# DA14682 register map
Vendor: Dialog; Series: DA14682; File version: 1.2
CPU: CM0 r1p0, little endian, MPU, FPU, 3 interrupt priority bits
Registers are 16-bit, read-write, reset 0x0 unless marked. A register's access mark holds for its fields unless they carry their own. Offsets are from the block's base; [hi:lo] are bit positions; {n}, {i} and the like mark numbered series.

## DCDC — DCDC registers
Base 0x50000080
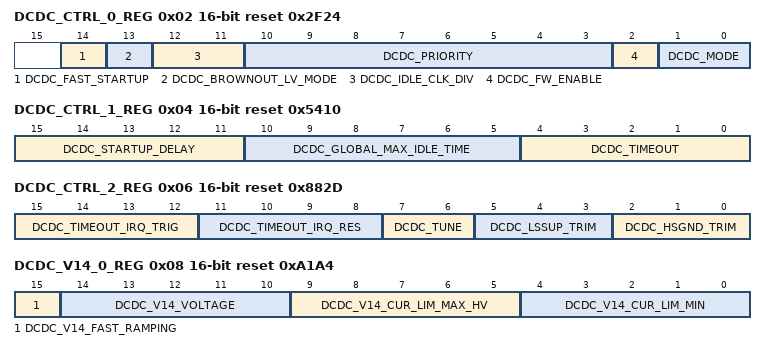
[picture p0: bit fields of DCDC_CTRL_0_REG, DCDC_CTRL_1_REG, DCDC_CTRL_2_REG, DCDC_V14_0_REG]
0x02 DCDC_CTRL_0_REG reset 0x2F24 — DCDC First Control Register
  [14] DCDC_FAST_STARTUP — Set current limit to maximum during initial startup
  [13] DCDC_BROWNOUT_LV_MODE — Switches to low voltage settings when battery voltage drops below 2.5 V
  [12:11] DCDC_IDLE_CLK_DIV — Idle Clock Divider 00 = 2 01 = 4 10 = 8 11 = 16
  [10:3] DCDC_PRIORITY — Charge priority register (4x 2 bit ID) Charge sequence is [1:0] > [3:2] > [5:4] > [7:6] ID[V14] = 00 ID[V18] = 01 ID[VDD] = 10 ID[V18P] = 11
  [2] DCDC_FW_ENABLE — Freewheel switch enable
  [1:0] DCDC_MODE — DCDC converter mode 00 = Disabled 01 = Active 10 = Sleep mode 11 = Disabled
0x04 DCDC_CTRL_1_REG reset 0x5410 — DCDC Second Control Register
  [15:11] DCDC_STARTUP_DELAY — Delay between turning bias on and converter becoming active 0 - 31 us, 1 us step size
  [10:5] DCDC_GLOBAL_MAX_IDLE_TIME — Global maximum idle time The current limit of any output that is idle for this long will be downramped faster than normal 0 - 7875 ns, 125 ns step size
  [4:0] DCDC_TIMEOUT — P and N switch timeout, if switch is closed longer than this a timeout is generated and the FSM is forced to the next state Writing 0 disables timeout functionality 62.5 - 1937.5 ns, 62.5 ns step size
0x06 DCDC_CTRL_2_REG reset 0x882D — DCDC Third Control Register
  [15:12] DCDC_TIMEOUT_IRQ_TRIG — Number of timeout events before timeout interrupt is generated
  [11:8] DCDC_TIMEOUT_IRQ_RES — Number of successive non-timed out charge events required to clear timeout event counter
  [7:6] DCDC_TUNE — Trim current sensing circuitry 00 = +0 percent 01 = +4 percent 10 = +8 percent 11 = +12 percent
  [5:3] DCDC_LSSUP_TRIM — Trim low side supply voltage V = 2 V + 100 mV * N
  [2:0] DCDC_HSGND_TRIM — Trim high side ground V = VBAT - (2.2 V + 200 mV * N)
0x08 DCDC_V14_0_REG reset 0xA1A4 — DCDC V14 First Control Register
  [15] DCDC_V14_FAST_RAMPING — V14 output fast current ramping (improves response time at the cost of more ripple)
  [14:10] DCDC_V14_VOLTAGE — V14 output voltage V = 1.2 V + 25 mV * N
  [9:5] DCDC_V14_CUR_LIM_MAX_HV — V14 output maximum current limit (high battery voltage mode) I = 30 mA * (1 + N)
  [4:0] DCDC_V14_CUR_LIM_MIN — V14 output minimum current limit I = 30 mA * (1 + N)
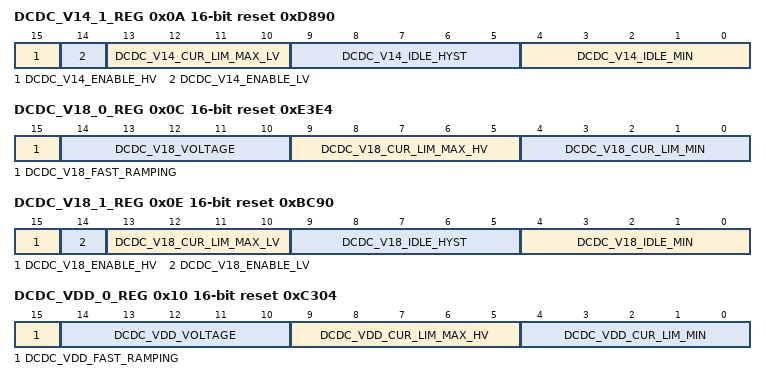
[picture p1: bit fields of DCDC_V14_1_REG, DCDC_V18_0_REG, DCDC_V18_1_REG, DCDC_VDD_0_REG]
0x0A DCDC_V14_1_REG reset 0xD890 — DCDC V14 Second Control Register
  [15] DCDC_V14_ENABLE_HV — V14 output enable (high battery voltage mode) 0 = Disabled 1 = Enabled
  [14] DCDC_V14_ENABLE_LV — V14 output enable (low battery voltage mode) 0 = Disabled 1 = Enabled
  [13:10] DCDC_V14_CUR_LIM_MAX_LV — V14 output maximum current limit low battery voltage mode) I = 30 mA * (1 + N)
  [9:5] DCDC_V14_IDLE_HYST — V14 output idle time hysteresis 0 - 3875 ns, 125 ns step size IDLE_MAX = IDLE_MIN + IDLE_HYST Maximum idle time before decreasing CUR_LIM
  [4:0] DCDC_V14_IDLE_MIN — V14 output minimum idle time 0 - 3875 ns, 125 ns step size Minimum idle time, CUR_LIM is increased if this limit is not reached
0x0C DCDC_V18_0_REG reset 0xE3E4 — DCDC V18 First Control Register
  [15] DCDC_V18_FAST_RAMPING — V18 output fast current ramping (improves response time at the cost of more ripple)
  [14:10] DCDC_V18_VOLTAGE — V18 output voltage V = 1.2 V + 25 mV * N
  [9:5] DCDC_V18_CUR_LIM_MAX_HV — V18 output maximum current limit (high battery voltage mode) I = 30 mA * (1 + N)
  [4:0] DCDC_V18_CUR_LIM_MIN — V18 output minimum current limit I = 30 mA * (1 + N)
0x0E DCDC_V18_1_REG reset 0xBC90 — DCDC V18 Second Control Register
  [15] DCDC_V18_ENABLE_HV — V18 output enable (high battery voltage mode) 0 = Disabled 1 = Enabled
  [14] DCDC_V18_ENABLE_LV — V18 output enable (low battery voltage mode) 0 = Disabled 1 = Enabled
  [13:10] DCDC_V18_CUR_LIM_MAX_LV — V18 output maximum current limit low battery voltage mode) I = 30 mA * (1 + N)
  [9:5] DCDC_V18_IDLE_HYST — V18 output idle time hysteresis 0 - 3875 ns, 125 ns step size IDLE_MAX = IDLE_MIN + IDLE_HYST Maximum idle time before decreasing CUR_LIM
  [4:0] DCDC_V18_IDLE_MIN — V18 output minimum idle time 0 - 3875 ns, 125 ns step size Minimum idle time, CUR_LIM is increased if this limit is not reached
0x10 DCDC_VDD_0_REG reset 0xC304 — DCDC VDD First Control Register
  [15] DCDC_VDD_FAST_RAMPING — VDD output fast current ramping (improves response time at the cost of more ripple)
  [14:10] DCDC_VDD_VOLTAGE — VDD output voltage V = 0.8 V + 25 mV * N
  [9:5] DCDC_VDD_CUR_LIM_MAX_HV — VDD output maximum current limit (high battery voltage mode) I = 30 mA * (1 + N)
  [4:0] DCDC_VDD_CUR_LIM_MIN — VDD output minimum current limit I = 30 mA * (1 + N)
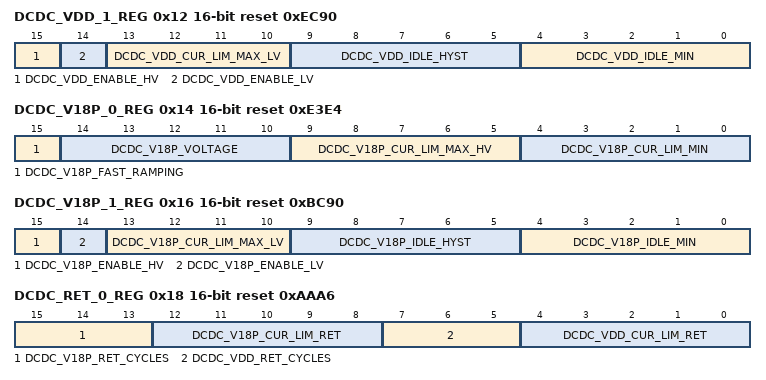
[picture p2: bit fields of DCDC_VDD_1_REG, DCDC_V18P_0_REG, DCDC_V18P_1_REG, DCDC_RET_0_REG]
0x12 DCDC_VDD_1_REG reset 0xEC90 — DCDC VDD Second Control Register
  [15] DCDC_VDD_ENABLE_HV — VDD output enable (high battery voltage mode) 0 = Disabled 1 = Enabled
  [14] DCDC_VDD_ENABLE_LV — VDD output enable (low battery voltage mode) 0 = Disabled 1 = Enabled
  [13:10] DCDC_VDD_CUR_LIM_MAX_LV — VDD output maximum current limit low battery voltage mode) I = 30 mA * (1 + N)
  [9:5] DCDC_VDD_IDLE_HYST — VDD output idle time hysteresis 0 - 3875 ns, 125 ns step size IDLE_MAX = IDLE_MIN + IDLE_HYST Maximum idle time before decreasing CUR_LIM
  [4:0] DCDC_VDD_IDLE_MIN — VDD output minimum idle time 0 - 3875 ns, 125 ns step size Minimum idle time, CUR_LIM is increased if this limit is not reached
0x14 DCDC_V18P_0_REG reset 0xE3E4 — DCDC VPA First Control Register
  [15] DCDC_V18P_FAST_RAMPING — V18P output fast current ramping (improves response time at the cost of more ripple)
  [14:10] DCDC_V18P_VOLTAGE — V18P output voltage V = 1.2 V + 25 mV * N
  [9:5] DCDC_V18P_CUR_LIM_MAX_HV — V18P output maximum current limit (high battery voltage mode) I = 30 mA * (1 + N)
  [4:0] DCDC_V18P_CUR_LIM_MIN — V18P output minimum current limit I = 30 mA * (1 + N)
0x16 DCDC_V18P_1_REG reset 0xBC90 — DCDC VPA Second Control Register
  [15] DCDC_V18P_ENABLE_HV — V18P output enable (high battery voltage mode) 0 = Disabled 1 = Enabled
  [14] DCDC_V18P_ENABLE_LV — V18P output enable (low battery voltage mode) 0 = Disabled 1 = Enabled
  [13:10] DCDC_V18P_CUR_LIM_MAX_LV — V18P output maximum current limit low battery voltage mode) I = 30 mA * (1 + N)
  [9:5] DCDC_V18P_IDLE_HYST — V18P output idle time hysteresis 0 - 3875 ns, 125 ns step size IDLE_MAX = IDLE_MIN + IDLE_HYST Maximum idle time before decreasing CUR_LIM
  [4:0] DCDC_V18P_IDLE_MIN — V18P output minimum idle time 0 - 3875 ns, 125 ns step size Minimum idle time, CUR_LIM is increased if this limit is not reached
0x18 DCDC_RET_0_REG reset 0xAAA6 — DCDC First Retention Mode Register
  [15:13] DCDC_V18P_RET_CYCLES — Charge cycles for V18P output in sleep mode Cycles = 1 + 2 * N
  [12:8] DCDC_V18P_CUR_LIM_RET — V18P output sleep mode current limit I = 30 mA * (1 + N)
  [7:5] DCDC_VDD_RET_CYCLES — Charge cycles for VDD output in sleep mode Cycles = 1 + 2 * N
  [4:0] DCDC_VDD_CUR_LIM_RET — VDD output sleep mode current limit I = 30 mA * (1 + N)
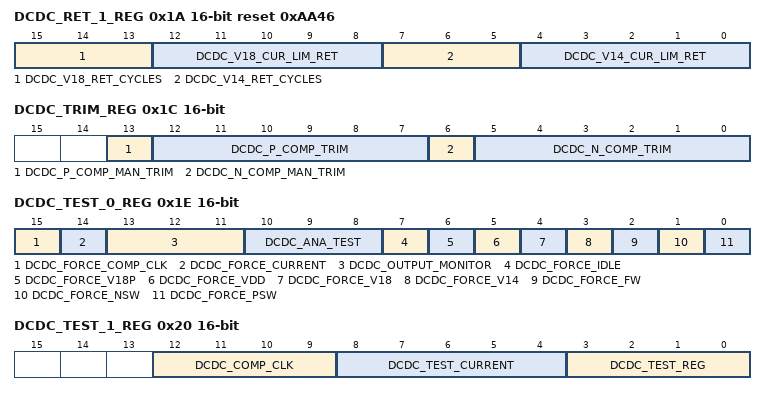
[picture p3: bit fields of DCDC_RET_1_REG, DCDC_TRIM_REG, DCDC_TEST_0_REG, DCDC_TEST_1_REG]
0x1A DCDC_RET_1_REG reset 0xAA46 — DCDC Second Retention Mode Register
  [15:13] DCDC_V18_RET_CYCLES — Charge cycles for V18 output in sleep mode Cycles = 1 + 2 * N
  [12:8] DCDC_V18_CUR_LIM_RET — V18 output sleep mode current limit I = 30 mA * (1 + N)
  [7:5] DCDC_V14_RET_CYCLES — Charge cycles for V14 output in sleep mode Cycles = 1 + 2 * N
  [4:0] DCDC_V14_CUR_LIM_RET — V14 output sleep mode current limit I = 30 mA * (1 + N)
0x1C DCDC_TRIM_REG — DCDC Comparator Trim Register
  [13] DCDC_P_COMP_MAN_TRIM — Trim mode for P side comparator 0 = Automatic 1 = Manual
  [12:7] DCDC_P_COMP_TRIM — Manual trim value for P side comparator Signed magnitude representation 011111 = +47 mV 000000 = 100000 = +16 mV 111111 = -15 mV
  [6] DCDC_N_COMP_MAN_TRIM — Trim mode for N side comparator 0 = Automatic 1 = Manual
  [5:0] DCDC_N_COMP_TRIM — Manual trim value for N side comparator Signed magnitude representation 011111 = +13 mV 000000 = 100000 = -22 mV 111111 = -56 mV
0x1E DCDC_TEST_0_REG — DCDC Test Register
  [15] DCDC_FORCE_COMP_CLK — Disables automatic comparator clock, clock lines values based on DCDC_COMP_CLK
  [14] DCDC_FORCE_CURRENT — Force output current setting
  [13:11] DCDC_OUTPUT_MONITOR — Output monitor switch (connect to ADC) 000 = None 001 = V14 010 = V18 011 = VDD 100 = VPA 101 = None 110 = None 111 = None
  [10:8] DCDC_ANA_TEST — Analog test bus 000 = None 001 = High side ground 010 = Low side supply 011 = 1.2 V buffer output 100 = None 101 = None 110 = None 111 = None
  [7] DCDC_FORCE_IDLE — Force idle mode
  [6] DCDC_FORCE_V18P — Force V18P switch on
  [5] DCDC_FORCE_VDD — Force VDD switch on
  [4] DCDC_FORCE_V18 — Force V18 switch on
  [3] DCDC_FORCE_V14 — Force V14 switch on
  [2] DCDC_FORCE_FW — Force FW switch on
  [1] DCDC_FORCE_NSW — Force N switch on
  [0] DCDC_FORCE_PSW — Force P switch on
0x20 DCDC_TEST_1_REG — DCDC Test Register
  [12:9] DCDC_COMP_CLK — Forced clock values for [COMP_VPA, COMP_VDD, COMP_V18, COMP_V14] (requires DCDC_FORCE_COMP_CLK = 1)
  [8:4] DCDC_TEST_CURRENT — Current limit setting when current limit is forced
  [3:0] DCDC_TEST_REG — Determines which register appears on the testbus 0x0 = DCDC_NONE 0x1 = DCDC_STATUS_0 0x2 = DCDC_STATUS_1 0x3 = DCDC_STATUS_2 0x4 = DCDC_STATUS_3 0x5 = DCDC_STATUS_4 0x6 = DCDC_TRIM_0 0x7 = DCDC_TRIM_1 0x8 = DCDC_TRIM_2 0x9 = DCDC_TRIM_3 0xA-0xF = DCDC_NONE
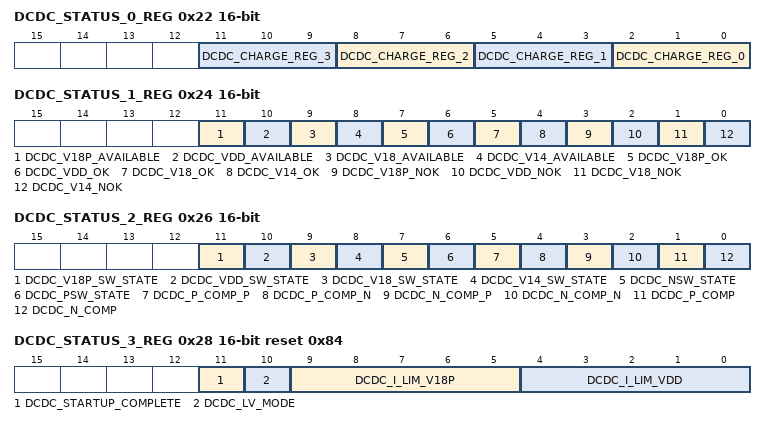
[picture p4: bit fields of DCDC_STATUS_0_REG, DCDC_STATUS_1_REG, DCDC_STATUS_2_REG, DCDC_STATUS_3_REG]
0x22 DCDC_STATUS_0_REG — DCDC First Status Register
  [3n+2:3n] DCDC_CHARGE_REG_{n} ro (n=0..3) — Charge register position {n}
0x24 DCDC_STATUS_1_REG — DCDC Second Status Register
  [11] DCDC_V18P_AVAILABLE ro — Indicates whether V18P is available Requires that converter is enabled, output is enabled and V_OK and V_NOK have both occured
  [10] DCDC_VDD_AVAILABLE ro — Indicates whether VDD is available Requires that converter is enabled, output is enabled and V_OK and V_NOK have both occured
  [9] DCDC_V18_AVAILABLE ro — Indicates whether V18 is available Requires that converter is enabled, output is enabled and V_OK and V_NOK have both occured
  [8] DCDC_V14_AVAILABLE ro — Indicates whether V14 is available Requires that converter is enabled, output is enabled and V_OK and V_NOK have both occured
  [7] DCDC_V18P_OK ro — OK output of V18P comparator
  [6] DCDC_VDD_OK ro — OK output of VDD comparator
  [5] DCDC_V18_OK ro — OK output of V18 comparator
  [4] DCDC_V14_OK ro — OK output of V14 comparator
  [3] DCDC_V18P_NOK ro — NOK output of V18P comparator
  [2] DCDC_VDD_NOK ro — NOK output of VDD comparator
  [1] DCDC_V18_NOK ro — NOK output of V18 comparator
  [0] DCDC_V14_NOK ro — NOK output of V14 comparator
0x26 DCDC_STATUS_2_REG — DCDC Third Status Register
  [11] DCDC_V18P_SW_STATE ro — DCDC state machine V18P output
  [10] DCDC_VDD_SW_STATE ro — DCDC state machine VDD output
  [9] DCDC_V18_SW_STATE ro — DCDC state machine V18 output
  [8] DCDC_V14_SW_STATE ro — DCDC state machine V14 output
  [7] DCDC_NSW_STATE ro — DCDC state machine NSW output
  [6] DCDC_PSW_STATE ro — DCDC state machine PSW output
  [5] DCDC_P_COMP_P ro — DCDC P side dynamic comparator P output
  [4] DCDC_P_COMP_N ro — DCDC P side dynamic comparator N output
  [3] DCDC_N_COMP_P ro — DCDC N side dynamic comparator P output
  [2] DCDC_N_COMP_N ro — DCDC N side dynamic comparator N output
  [1] DCDC_P_COMP ro — DCDC P side continuous time comparator output
  [0] DCDC_N_COMP ro — DCDC N side continuous time comparator output
0x28 DCDC_STATUS_3_REG reset 0x84 — DCDC Fourth Status Register
  [11] DCDC_STARTUP_COMPLETE ro — Indicates if the converter is enabled and the startup counter has expired (internal biasing settled)
  [10] DCDC_LV_MODE ro — Indicates if the converter is in low battery voltage mode
  [9:5] DCDC_I_LIM_V18P ro — Actual V18P current limit
  [4:0] DCDC_I_LIM_VDD ro — Actual VDD current limit
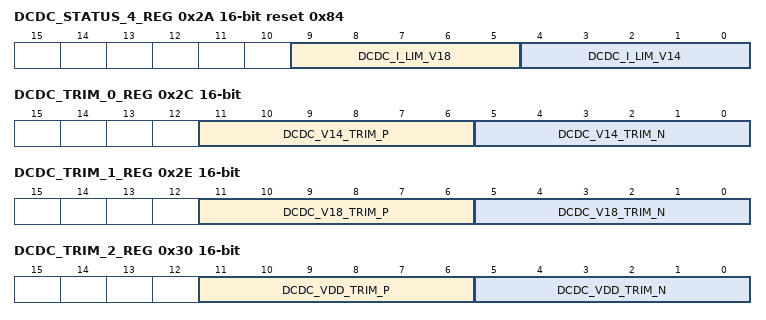
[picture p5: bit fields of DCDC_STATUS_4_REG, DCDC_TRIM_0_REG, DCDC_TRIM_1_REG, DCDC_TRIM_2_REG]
0x2A DCDC_STATUS_4_REG reset 0x84 — DCDC Fifth Status Register
  [9:5] DCDC_I_LIM_V18 ro — Actual V18 current limit
  [4:0] DCDC_I_LIM_V14 ro — Actual V14 current limit
0x2C DCDC_TRIM_0_REG — DCDC V14 Comparator Trim Register
  [11:6] DCDC_V14_TRIM_P ro — P comparator trim value when V14 is active Signed magnitude representation 011111 = +47 mV 000000 = 100000 = +16 mV 111111 = -15 mV
  [5:0] DCDC_V14_TRIM_N ro — N comparator trim value when V14 is active Signed magnitude representation 011111 = +13 mV 000000 = 100000 = -22 mV 111111 = -56 mV
0x2E DCDC_TRIM_1_REG — DCDC V18 Comparator Trim Register
  [11:6] DCDC_V18_TRIM_P ro — P comparator trim value when V18 is active Signed magnitude representation 011111 = +47 mV 000000 = 100000 = +16 mV 111111 = -15 mV
  [5:0] DCDC_V18_TRIM_N ro — N comparator trim value when V18 is active Signed magnitude representation 011111 = +13 mV 000000 = 100000 = -22 mV 111111 = -56 mV
0x30 DCDC_TRIM_2_REG — DCDC VDD Comparator Trim Register
  [11:6] DCDC_VDD_TRIM_P ro — P comparator trim value when VDD is active Signed magnitude representation 011111 = +47 mV 000000 = 100000 = +16 mV 111111 = -15 mV
  [5:0] DCDC_VDD_TRIM_N ro — N comparator trim value when VDD is active Signed magnitude representation 011111 = +13 mV 000000 = 100000 = -22 mV 111111 = -56 mV
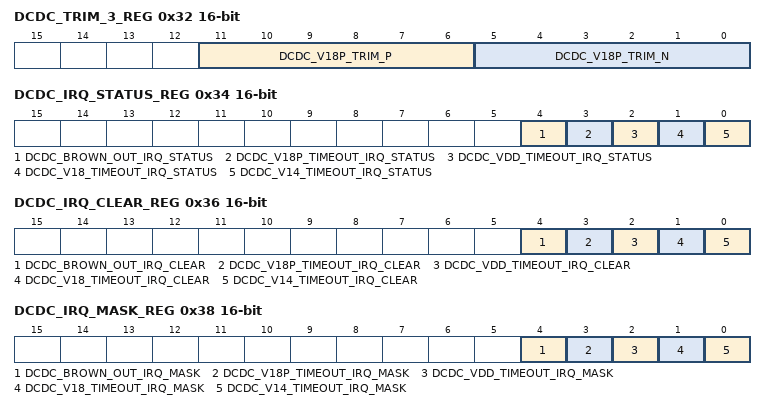
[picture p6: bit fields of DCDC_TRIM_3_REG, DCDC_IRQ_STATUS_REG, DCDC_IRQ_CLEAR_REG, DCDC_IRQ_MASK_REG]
0x32 DCDC_TRIM_3_REG — DCDC VPA Comparator Trim Register
  [11:6] DCDC_V18P_TRIM_P ro — P comparator trim value when V18P is active Signed magnitude representation 011111 = +47 mV 000000 = 100000 = +16 mV 111111 = -15 mV
  [5:0] DCDC_V18P_TRIM_N ro — N comparator trim value when V18P is active Signed magnitude representation 011111 = +13 mV 000000 = 100000 = -22 mV 111111 = -56 mV
0x34 DCDC_IRQ_STATUS_REG — DCDC Interrupt Status Register
  [4] DCDC_BROWN_OUT_IRQ_STATUS ro — Brown out detector triggered (battery voltage below 2.5 V)
  [3] DCDC_V18P_TIMEOUT_IRQ_STATUS ro — Timeout occured on V18P output
  [2] DCDC_VDD_TIMEOUT_IRQ_STATUS ro — Timeout occured on VDD output
  [1] DCDC_V18_TIMEOUT_IRQ_STATUS ro — Timeout occured on V18 output
  [0] DCDC_V14_TIMEOUT_IRQ_STATUS ro — Timeout occured on V14 output
0x36 DCDC_IRQ_CLEAR_REG — DCDC Interrupt Clear Register
  [4] DCDC_BROWN_OUT_IRQ_CLEAR wo — Clear brown out interrupt
  [3] DCDC_V18P_TIMEOUT_IRQ_CLEAR wo — Clear V18P timeout interrupt
  [2] DCDC_VDD_TIMEOUT_IRQ_CLEAR wo — Clear VDD timeout interrupt
  [1] DCDC_V18_TIMEOUT_IRQ_CLEAR wo — Clear V18 timeout interrupt
  [0] DCDC_V14_TIMEOUT_IRQ_CLEAR wo — Clear V14 timeout interrupt
0x38 DCDC_IRQ_MASK_REG — DCDC Interrupt Clear Register
  [4] DCDC_BROWN_OUT_IRQ_MASK — Mask brown out interrupt
  [3] DCDC_V18P_TIMEOUT_IRQ_MASK — Mask V18P timeout interrupt
  [2] DCDC_VDD_TIMEOUT_IRQ_MASK — Mask VDD timeout interrupt
  [1] DCDC_V18_TIMEOUT_IRQ_MASK — Mask V18 timeout interrupt
  [0] DCDC_V14_TIMEOUT_IRQ_MASK — Mask V14 timeout interrupt
